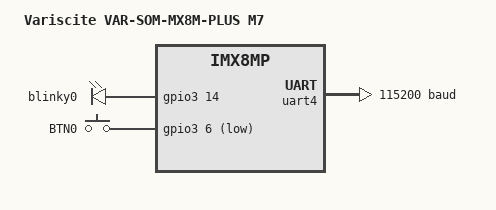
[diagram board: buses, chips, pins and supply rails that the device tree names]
/*
 * Copyright 2025 Variscite Ltd.
 * Copyright (c) 2021, Laird Connectivity
 *
 * SPDX-License-Identifier: Apache-2.0
 */

/dts-v1/;

#include <nxp/nxp_imx8ml_m7.dtsi>
#include "imx8mp_var_som-pinctrl.dtsi"
#include <zephyr/dt-bindings/gpio/gpio.h>
#include <zephyr/dt-bindings/input/input-event-codes.h>

/ {
	model = "Variscite VAR-SOM-MX8M-PLUS M7";
	compatible = "nxp,imx8mp_var_som";

	chosen {
		/* TCM */
		zephyr,flash = &itcm;
		zephyr,sram = &dtcm;

		zephyr,console = &uart4;
		zephyr,shell-uart = &uart4;
	};

	aliases {
		led0 = &blinky0;
		sw0 = &button0;
	};

	leds {
		compatible = "gpio-leds";

		blinky0: blinky_0 {
			gpios = <&gpio3 14 GPIO_ACTIVE_HIGH>;
		};
	};

	keys {
		compatible = "gpio-keys";

		button0: btn_0 {
			label = "BTN0";
			gpios = <&gpio3 6 (GPIO_PULL_UP | GPIO_ACTIVE_LOW)>;
			zephyr,code = <INPUT_KEY_0>;
		};
	};
};

&uart4 {
	status = "okay";
	current-speed = <115200>;
	pinctrl-0 = <&uart4_default>;
	pinctrl-names = "default";
};

&gpio3 {
	status = "okay";
};

&mailbox0 {
	status = "okay";
};
